# MCRC register map
Vendor: Texas Instruments
Peripheral module from a debugger description file (folder TDA3x).
Registers are 32-bit, read-write, reset 0x0 unless marked. A register's access mark holds for its fields unless they carry their own. Offsets are as the file gives them; lines under a group give offsets from that group; [hi:lo] are bit positions; {n}, {i} and the like mark numbered series; 'fields as' and 'values as' point back to an identical list; <NAME> marks a mode.

## MCRC
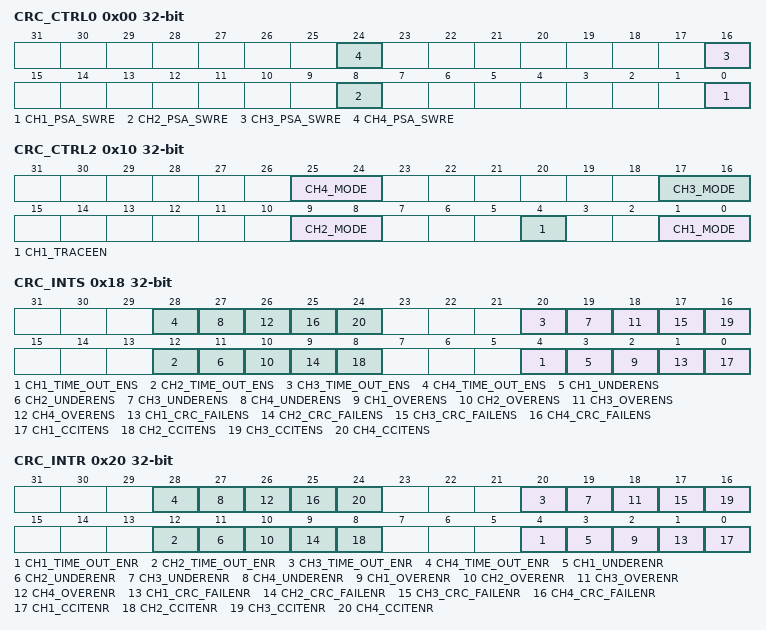
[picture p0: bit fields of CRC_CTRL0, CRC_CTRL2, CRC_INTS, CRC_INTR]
0x00 CRC_CTRL0 access per field
  [8n-8] CH{n}_PSA_SWRE rw (n=1..4) — Channel {n} PSA Software Reset. When set, the PSA Signature Register is reset to all zero. Software reset does not reset software reset bit itself. Therefore, CPU is required to clear this bit by writing a 0 . 0 = PSA Signature Register not reset 1 = PSA Signature Register reset
0x08 CRC_CTRL1 access per field
  [0] PWDN rw — Power Down. When set, MCRC Module is put in power down mode. 0 = MCRC is not in power down mode. 1 = MCRC is in power down mode.
0x10 CRC_CTRL2 access per field — Data capture mode is especially useful when it is used in conjunction when data trace (CH1_TRACEEN) for channel 1. The seed value can be planted in PSA Signature Register during data capture mode by writing a seed value into PSA Signature Register. Data trace enable bit is then set to snoop and compress any read transaction on Data buses. When trace enable bit is set, CH1_MODE is automatically reset to data capture mode. To change mode from one to another in the middle of an on-going mode user should take the following steps:
  [25:24] CH4_MODE rw — Channel 4 Mode. 00 = Data Capture mode. In this mode, the PSA Signature Register does not compress data when it is written. Any data written to PSA Signature Register is simply captured by PSA Signature Register without any compression. This mode can be used to plant seed value into the PSA register. 01 = AUTO mode 10 = 11 = Full-CPU mode For all four channels the seed value can be first planted into PSA register before the Channel Mode is switched to Full-CPU mode since host CPU controls the amount of data for compression. During AUTO mode, the PSA register is automatically reset to zero at the end of each sector compression.
  [17:16] CH3_MODE rw — Channel 3 Mode. 00 = Data Capture mode. In this mode, the PSA Signature Register does not compress data when it is written. Any data written to PSA Signature Register is simply captured by PSA Signature Register without any compression. This mode can be used to plant seed value into the PSA register. 01 = AUTO mode 10 = 11 = Full-CPU mode
  [9:8] CH2_MODE rw — Channel 2 Mode. 00 = Data Capture mode. In this mode, the PSA Signature Register does not compress data when it is written. Any data written to PSA Signature Register is simply captured by PSA Signature Register without any compression. This mode can be used to plant seed value into the PSA register. 01 = AUTO mode 10 = 11 = Full-CPU mode
  [4] CH1_TRACEEN rw — Channel 1 Data Trace Enable When set, the channel is put into data trace mode. The channel snoops on the CPU VBUSM, ITCM, DTCM buses for any read transaction. Any read data on these buses is compressed by the PSA Signature Register. When suspend is on, the PSA Signature Register does not compress any read data on these buses. 0 = Data Trace disable 1 = Data Trace enable
  [1:0] CH1_MODE rw — Channel 1 Mode. 00 = Data Capture mode. In this mode, the PSA Signature Register does not compress data when it is written. Any data written to PSA Signature Register is simply captured by PSA Signature Register without any compression. This mode can be used to plant seed value into the PSA register. 01 = AUTO mode 10 = 11 = Full-CPU mode
0x18 CRC_INTS access per field
  [8n-4] CH{n}_TIME_OUT_ENS rw (n=1..4) — Channel {n} Timeout Interrupt Enable Bit Writing a one to this bit enable the timeout interrupt. Writing a zero has no effect. Reading from this bit gives the status (interrupt enable/disable). User and privileged mode read: 0 = Timeout Interrupt disable 1 = Timeout Interrupt enable User and privileged mode write: 0 = Has no effect 1 = Timeout Interrupt enable
  [8n-5] CH{n}_UNDERENS rw (n=1..4) — Channel {n} Underrun Interrupt Enable Bit Writing a one to this bit enable the underrun interrupt. Writing a zero has no effect. Reading from this bit gives the status (interrupt enable/disable). User and privileged mode read: 0 = Underrun Interrupt disable 1 = Underrun Interrupt enable User and privileged mode write: 0 = Has no effect 1 = Underrun Interrupt enable
  [8n-6] CH{n}_OVERENS rw (n=1..4) — Channel {n} Overrun Interrupt Enable Bit Writing a one to this bit enable the overrun interrupt. Writing a zero has no effect. Reading from this bit gives the status (interrupt enable/disable). User and privileged mode read: 0 = Overrun Interrupt disable 1 = Overrun Interrupt enable User and privileged mode write: 0 = Has no effect 1 = Overrun Interrupt enable
  [8n-7] CH{n}_CRC_FAILENS rw (n=1..4) — Channel {n} CRC Fail Interrupt Enable Bit. Writing a one to this bit enable the CRC fail interrupt. Writing a zero has no effect. Reading from this bit gives the status (interrupt enable/disable). User and privileged mode read: 0 = CRC Fail Interrupt disable 1 = CRC Fail Interrupt enable User and privileged mode write: 0 = Has no effect 1 = CRC Fail Interrupt enable
  [8n-8] CH{n}_CCITENS rw (n=1..4) — Channel {n} Compression Complete Interrupt Enable Bit. Writing a one to this bit enable the CRC fail interrupt. Writing a zero has no effect. Reading from this bit gives the status (interrupt enable/disable). User and privileged mode read: 0 = Compression Complete Interrupt disable 1 = Compression Complete Interrupt enable User and privileged mode write: 0 = Has no effect 1 = Compression Complete Interrupt enable
0x20 CRC_INTR access per field
  [8n-4] CH{n}_TIME_OUT_ENR rw (n=1..4) — Channel {n} Timeout Interrupt Disable Bit Writing a one to this bit disable the timeout interrupt. Writing a zero has no effect. Reading from this bit gives the status (interrupt enable/disable). User and privileged mode read: 0 = Timeout Interrupt disable 1 = Timeout Interrupt enable User and privileged mode write: 0 = Has no effect 1 = Timeout Interrupt enable
  [8n-5] CH{n}_UNDERENR rw (n=1..4) — Channel {n} Underrun Interrupt Disable Bit Writing a one to this bit disable the underrun interrupt. Writing a zero has no effect. Reading from this bit gives the status (interrupt enable/disable). User and privileged mode read: 0 = Underrun Interrupt disable 1 = Underrun Interrupt enable User and privileged mode write: 0 = Has no effect 1 = Underrun Interrupt enable
  [8n-6] CH{n}_OVERENR rw (n=1..4) — Channel {n} Overrun Interrupt Disable Bit Writing a one to this bit disable the overrun interrupt. Writing a zero has no effect. Reading from this bit gives the status (interrupt enable/disable). User and privileged mode read: 0 = Overrun Interrupt disable 1 = Overrun Interrupt enable User and privileged mode write: 0 = Has no effect 1 = Overrun Interrupt enable
  [8n-7] CH{n}_CRC_FAILENR rw (n=1..4) — Channel {n} CRC Fail Interrupt Disable Bit. Writing a one to this bit disable the CRC fail interrupt. Writing a zero has no effect. Reading from this bit gives the status (interrupt enable/disable). User and privileged mode read: 0 = CRC Fail Interrupt disable 1 = CRC Fail Interrupt enable User and privileged mode write: 0 = Has no effect 1 = CRC Fail Interrupt enable
  [8n-8] CH{n}_CCITENR rw (n=1..4) — Channel {n} Compression Complete Interrupt Disable Bit Writing a one to this bit disable the CRC fail interrupt. Writing a zero has no effect. Reading from this bit gives the status (interrupt enable/disable) User and privileged mode read: 0 = Compression Complete Interrupt disable 1 = Compression Complete Interrupt enable User and privileged mode write: 0 = Has no effect 1 = Compression Complete Interrupt disable
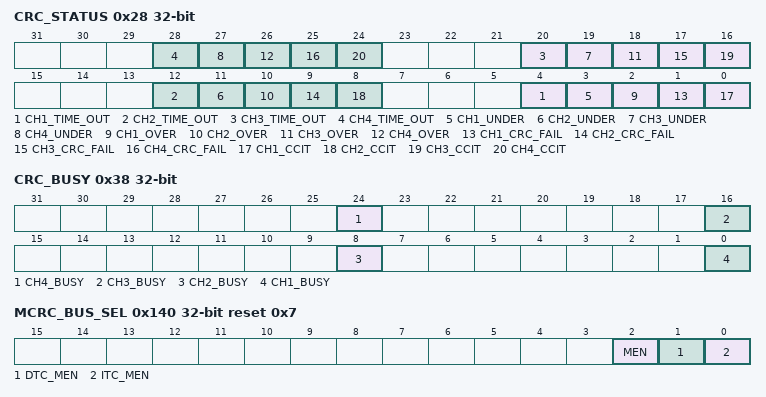
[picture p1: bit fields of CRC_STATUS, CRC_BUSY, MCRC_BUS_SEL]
0x28 CRC_STATUS access per field
  [8n-4] CH{n}_TIME_OUT rw (n=1..4) — Channel {n} CRC Timeout Status Flag This bit is cleared by writing a 1 to it only. Writing 0 has no effect. This bit is set in AUTO mode. 0 = No timeout interrupt is active 1 = Timeout interrupt is active
  [8n-5] CH{n}_UNDER rw (n=1..4) — Channel {n} CRC Underrun Status Flag. This bit is cleared by writing a 1 to it only. Writing 0 has no effect. This bit is set in AUTO mode only 0 = No underrun interrupt is active 1 = Underrun interrupt is active
  [8n-6] CH{n}_OVER rw (n=1..4) — Channel {n} CRC Overrun Status Flag This bit is cleared by writing a 1 to it only. Writing 0 has no effect. This bit is set in AUTO mode 0 = No overrun interrupt is active 1 = Overrun interrupt is active
  [8n-7] CH{n}_CRC_FAIL rw (n=1..4) — Channel {n} CRC Compare Fail Status Flag. This bit is cleared by writing a 1 to it only. Writing 0 has no effect. This bit is set in AUTO mode only. 0 = No CRC compare fail interrupt is active 1 = CRC compare fail interrupt is active
  [8n-8] CH{n}_CCIT rw (n=1..4) — Channel {n} CRC Pattern Compression Complete Status Flag. This bit is cleared by writing a ?1? to it only. Writing ?0? has no effect. This bit is only set in Semi-CPU mode. 0 = No CRC pattern compression complete interrupt is active 1 = CRC pattern compression complete interrupt is active
0x30 CRC_INT_OFFSET_REG access per field
  [7:0] CRC rw — Interrupt Offset. ARRAY(0x2439fb0)
0x38 CRC_BUSY ro
  [24] CH4_BUSY — ARRAY(0x243e780)
  [16] CH3_BUSY — ARRAY(0x243e9a0)
  [8] CH2_BUSY — ARRAY(0x243eba0)
  [0] CH1_BUSY — ARRAY(0x243eda0)
0x40 CRC_PCOUNT_REG1 access per field
  [19:0] CRC_PAT_COUNT1 rw — Channel 1 Pattern Counter Preload Register. This register contains the number of data patterns in one sector to be compressed before a CRC is performed.
0x44 CRC_SCOUNT_REG1 access per field
  [15:0] CRC_SEC_COUNT1 rw — Channel 1 Sector Counter Preload Register. This register contains the number of sectors in one block of memory.
0x48 CRC_CURSEC_REG1 access per field
  [15:0] CRC_CURSEC1 rw — Channel 1 Current Sector ID Register. In AUTO mode, this register contains the current sector number of which the signature verification fails. The sector counter is a free running up counter. When a sector fails, the erroneous sector number is logged into current sector ID register and the CRC fail interrupt is generated The sector ID register is frozen until it is read and the CRC fail status bit is cleared by CPU. While it is frozen, it does not capture another erroneous sector number. When this condition happens, an overrun interrupt is generated instead. Once the register is read and the CRC fail interrupt flag is cleared it can capture new erroneous sector number.
0x4C CRC_WDTOPLD1 access per field
  [23:0] CRC_WDTOPLD1 rw — Channel 1 Watchdog Timeout Counter Preload Register. This register contains the number of clock cycles within which the DMA must transfer the next block of data patterns.
0x50 CRC_BCTOPLD1 access per field
  [23:0] CRC_BCTOPLD1 rw — Channel 1 Block Complete Timeout Counter Preload Register. This register contains the number of clock cycles within which the CRC for an entire block needs to complete before a timeout interrupt is generated.
{0x20+0x40*i} PSA_SIGREGL{i} (i=1..3)
  [31:0] PSASIG{i} — Channel {i} PSA Signature Low Register. This register contains the value stored at PSASIG{i}[31:0] register.
{0x24+0x40*i} PSA_SIGREGH{i} (i=1..3)
  [31:0] PSASIG{i}_63_32 — Channel {i} PSA Signature High Register. This register contains the value stored at PSASIG{i}[63:32] register.
{0x28+0x40*i} CRC_REGL{i} (i=1..3)
  [31:0] CRC{i} — Channel {i} CRC Value Low Register. This register contains the current known good signature value stored at CRC{i}[31:0] register.
0x6C CRC_REGH1
  [31:0] CRC1_47_32 — Channel 1 CRC Value High Register. This register contains the current known good signature value stored at CRC1[63:32] register.
{0x30+0x40*i} PSA_SECSIGREGL{i} (i=1..3)
  [31:0] PSASECSIG{i} — Channel {i} PSA Sector Signature Low Register. This register contains the value stored at PSASECSIG{i}[31:0] register.
0x74 PSA_SECSIGREGH1
  [31:0] PSASECSIG1 — Channel 1 PSA Sector Signature High Register. This register contains the value stored at PSASECSIG1[63:32] register.
{0x38+0x40*i} RAW_DATAREGL{i} (i=1..4)
  [31:0] RAW_DATA{i} — Channel {i} Raw Data Low Register. This register contains bit 31:0 of the uncompressed raw data.
0x7C RAW_DATAREGH1
  [31:0] RAW_DATA1_47_32 — Channel 1 Raw Data High Register. This register contains bit 63:32 of the uncompressed raw data.
0x80 CRC_PCOUNT_REG2
  [19:0] CRC_PAT_COUNT2 — CRC Pattern Counter Preload Register 2 This register contains the number of data patterns in one sector to be compressed before a CRC is performed.
0x84 CRC_SCOUNT_REG2
  [15:0] CRC_SEC_COUNT2 — Channel 2 Sector Counter Preload Register. This register contains the number of sectors in one block of memory.
0x88 CRC_CURSEC_REG2
  [15:0] CRC_CURSEC2 — Channel 2 Current Sector ID Register. In AUTO mode, this register contains the current sector number of which the signature verification fails. The sector counter is a free running up counter. When a sector fails, the erroneous sector number is logged into current sector ID register and the CRC fail interrupt is generated The sector ID register is frozen until it is read and the CRC fail status bit is cleared by CPU. While it is frozen, it does not capture another erroneous sector number. When this condition happens, an overrun interrupt is generated instead. Once the register is read and the CRC fail interrupt flag is cleared it can capture new erroneous sector number.
0x8C CRC_WDTOPLD2
  [23:0] CRC_WDTOPLD2 — Channel 2 Watchdog Timeout Counter Preload Register. This register contains the number of clock cycles within which the DMA must transfer the next block of data patterns.
0x90 CRC_BCTOPLD2
  [23:0] CRC_BCTOPLD2 — Channel 2 Block Complete Timeout Counter Preload Register. This register contains the number of clock cycles within which the CRC of an entire block needs to complete before a timeout interrupt is generated.
0xAC CRC_REGH2
  [31:0] CRC2_63_32 — Channel 2 CRC Value High Register. This register contains the current known good signature value stored at CRC2[63:32] register.
{0x34+0x40*i} PSA_SECSIGREGH{i} (i=2..4)
  [31:0] PSASECSIG{i}_63_32 — Channel {i} PSA Sector Signature High Register. This register contains the value stored at PSASECSIG{i}[63:32] register.
{0x3C+0x40*i} RAW_DATAREGH{i} (i=2..4)
  [31:0] RAW_DATA{i}_63_32 — Channel {i} Raw Data High Register. This register contains bit 63:32 of the uncompressed raw data.
0xC0 CRC_PCOUNT_REG3 access per field
  [19:0] CRC_PAT_COUNT3 rw — Channel 3 Pattern Counter Preload Register. This register contains the number of data patterns in one sector to be compressed before a CRC is performed.
0xC4 CRC_SCOUNT_REG3 access per field
  [15:0] CRC_SEC_COUNT3 rw — Channel 3 Sector Counter Preload Register. This register contains the number of sectors in one block of memory.
0xC8 CRC_CURSEC_REG3 access per field
  [15:0] CRC_CURSEC3 rw — Channel 3 Current Sector ID Register. In AUTO mode, this register contains the current sector number of which the signature verification fails. The sector counter is a free running up counter. When a sector fails, the erroneous sector number is logged into current sector ID register and the CRC fail interrupt is generated The sector ID register is frozen until it is read and the CRC fail status bit is cleared by CPU. While it is frozen, it does not capture another erroneous sector number. When this condition happens, an overrun interrupt is generated instead. Once the register is read and the CRC fail interrupt flag is cleared it can capture new erroneous sector number.
0xCC CRC_WDTOPLD3 access per field
  [15:0] CRC_WDTOPLD3 rw — Channel 3 Watchdog Timeout Counter Preload Register. This register contains the number of clock cycles within which the DMA must transfer the next block of data patterns.
0xD0 CRC_BCTOPLD3 access per field
  [23:0] CRC_BCTOPLD3 rw — Channel 3 Block Complete Timeout Counter Preload Register. This register contains the number of clock cycles within which the CRC of an entire block needs to complete before a timeout interrupt is generated.
0xEC CRC_REGH3
  [31:0] CRC3_63_32 — Channel 3 CRC Value High Register. This register contains the current known good signature value stored at CRC3[63:32] register.
0x100 CRC_PCOUNT_REG4 access per field
  [19:0] CRC_PAT_COUNT4 rw — Channel 4 Pattern Counter Preload Register. This register contains the number of data patterns in one sector to be compressed before a CRC is performed.
0x104 CRC_SCOUNT_REG4 access per field
  [15:0] CRC_SEC_COUNT4 rw — Channel 4 Sector Counter Preload Register. This register contains the number of sectors in one block of memory.
0x108 CRC_CURSEC_REG4 access per field
  [15:0] CRC_CURSEC4 rw — In AUTO mode, this register contains the current sector number of which the signature verification fails. The sector counter is a free running up counter. When a sector fails, the erroneous sector number is logged into current sector ID register and the CRC fail interrupt is generated The sector ID register is frozen until it is read and the CRC fail status bit is cleared by CPU. While it is frozen, it does not capture another erroneous sector number. When this condition happens, an overrun interrupt is generated instead. Once the register is read and the CRC fail interrupt flag is cleared it can capture new erroneous sector number. In Semi-CPU mode, this register is used to indicate the sector number for which the compression complete has last happened.
0x10C CRC_WDTOPLD4 access per field
  [23:0] CRC_WDTOPLD4 rw — This register contains the number of clock cycles within which the DMA must transfer the next block of data patterns.
0x110 CRC_BCTOPLD4 access per field
  [23:0] CRC_BCTOPLD4 rw — This register contains the number of clock cycles within which the CRC of an entire block needs to complete before a timeout interrupt is generated.
0x120 PSA_SIGREGL4 access per field
  [23:0] PSASIG4 rw — This register contains the value stored at PSASIG4[31:0] register.
0x124 PSA_SIGREGH4
  [31:0] PSASIG4_63_32 — This register contains the value stored at PSASIG4[63:32] register.
0x128 CRC_REGL4
  [31:0] CRC4 — Channel 4 CRC Value Low Register.
0x12C CRC_REGH4
  [31:0] CRC4_63_32 — Channel 4 CRC Value High Register.
0x130 PSA_SECSIGREGL4
  [31:0] PSASECSIG4 — Channel 4 PSA Sector Signature Low Register.
0x140 MCRC_BUS_SEL access per field reset 0x7
  [2] MEN rw — Enable/disables the tracing of VBUSM 0: Tracing of VBUSM master bus has been disabled 1: Tracing of VBUSM master bus has been enabled
  [1] DTC_MEN rw — Enable/disables the tracing of data TCM 0: Tracing of DTCM_ODD and DTCM_EVEN buses have been disabled 1: Tracing of DTCM_ODD and DTCM_EVEN buses have been enabled
  [0] ITC_MEN rw — Enable/disables the tracing of instruction TCM 0: Tracing of ITCM bus has been disabled 1: Tracing of ITCM bus has been enabled Please refer the description of CPU Data trace at page 1-21 for the priority between different data buses.
